AUTOSAR XML (schema 4-2-1)
standard types defined: boolean, sint16, sint8, uint16, uint8
package /ComponentTypes
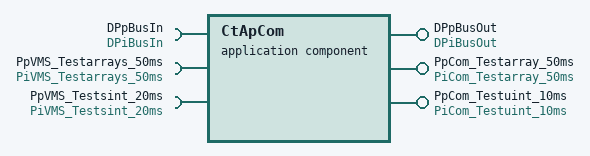
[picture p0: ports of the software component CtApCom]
  application sw component type CtApCom
    provide port DPpBusOut: provided-interface=DPiBusOut
      provided-com-specs:
        data-element=DPiBusOut/Element{0..4}, init-value=constant-reference=InitValueSpec_Reserved
        data-element=DPiBusOut/Element5, init-value=constant-reference=C_ARRAY_8_uint8
    provide port PpCom_Testarray_50ms: nonqueued-sender-com-spec{data-element=DeTestarray, init-value=constant-reference=C_RECORD_Testarray}, provided-interface=PiCom_Testarray_50ms
    provide port PpCom_Testuint_10ms: nonqueued-sender-com-spec{data-element=DeTestuint, init-value=constant-reference=C_RECORD_Testuint}, provided-interface=PiCom_Testuint_10ms
    require port DPpBusIn: required-interface=DPiBusIn
      required-com-specs:
        data-element=DPiBusIn/Element{0..4}, filter=data-filter-type=ALWAYS, init-value=constant-reference=InitValueSpec_Reserved
        data-element=DPiBusIn/Element5, filter=data-filter-type=ALWAYS, init-value=constant-reference=C_ARRAY_8_uint8
    require port PpVMS_Testarrays_50ms: nonqueued-receiver-com-spec{data-element=DeTestarrays, filter=data-filter-type=ALWAYS, init-value=constant-reference=C_RECORD_Testarrays}, required-interface=PiVMS_Testarrays_50ms
    require port PpVMS_Testsint_20ms: nonqueued-receiver-com-spec{data-element=DeTestsint, filter=data-filter-type=ALWAYS, init-value=constant-reference=C_RECORD_Testsint}, required-interface=PiVMS_Testsint_20ms
    behavior CtApCom_InternalBehavior
  composition sw component type ApplicationHost
    component CtApCom: type=CtApCom
  swc implementation CtApCom_Implementation: behavior=CtApCom_InternalBehavior
    code-descriptors:
      code Default: artifact-descriptors=autosar-engineering-object={short-label=Default, category=SWSRC}
package /Constants
  5 x constant specification:
    C_ARRAY_8_uint8: value-spec=8 x 0
    C_RECORD_Testarray: value-spec=fields=Element5:8 x 0
    C_RECORD_Testarrays: value-spec=fields=Element5:8 x 0
    C_RECORD_Testsint: value-spec=fields=[Element0:0, Element1:0, Element2:0, Element3:0, Element4:0]
    C_RECORD_Testuint: value-spec=fields=[Element0:0, Element1:0, Element2:0, Element3:0, Element4:0]
package /DataTypes
  11 x impl type, all with sw-calibration-access=READ-ONLY, type-emitter=RTE:
    Dt_Element0: category=VALUE, base-type=boolean
    Dt_Element1: category=VALUE, base-type=uint8
    Dt_Element2: category=VALUE, base-type=uint16
    Dt_Element3: category=VALUE, base-type=sint8
    Dt_Element4: category=VALUE, base-type=sint16
    Dt_Element5: category=ARRAY
      element Element: array-size=8, array-size-semantics=FIXED-SIZE, implementation-data-type=uint8
    Dt_RECORD_Testarray: category=STRUCTURE
      element Element5: implementation-data-type=Dt_Testarray
    Dt_RECORD_Testarrays: category=STRUCTURE
      element Element5: implementation-data-type=Dt_Element5
    Dt_RECORD_Testsint: category=STRUCTURE
      5 x element, all with category=TYPE_REFERENCE:
        Element0: implementation-data-type=boolean
        Element1: implementation-data-type=uint8
        Element2: implementation-data-type=uint16
        Element3: implementation-data-type=sint8
        Element4: implementation-data-type=sint16
    Dt_RECORD_Testuint: category=STRUCTURE
      5 x element, all with category=TYPE_REFERENCE:
        Element0: implementation-data-type=boolean
        Element1: implementation-data-type=uint8
        Element2: implementation-data-type=uint16
        Element3: implementation-data-type=sint8
        Element4: implementation-data-type=sint16
    Dt_Testarray: category=ARRAY
      element Element: array-size=8, array-size-semantics=FIXED-SIZE, implementation-data-type=uint8
package /DaVinci
  constant specification InitValueSpec_Reserved: value-spec=0
package /PortInterfaces
  6 x sender receiver interface:
    DPiBusIn
      6 x data:
        Element{0..5}: type=Dt_Element{0..5}
      invalidation-policys:
        data-element=DPiBusIn/Element{1..4}, handle-invalid=DONT-INVALIDATE
        data-element=DPiBusIn/Element0, handle-invalid=DONT-INVALIDATE
        data-element=DPiBusIn/Element5, handle-invalid=DONT-INVALIDATE
    DPiBusOut
      6 x data:
        Element{0..5}: type=Dt_Element{0..5}
      invalidation-policys:
        data-element=DPiBusOut/Element{1..4}, handle-invalid=DONT-INVALIDATE
        data-element=DPiBusOut/Element0, handle-invalid=DONT-INVALIDATE
        data-element=DPiBusOut/Element5, handle-invalid=DONT-INVALIDATE
    PiCom_Testarray_50ms: invalidation-policy{data-element=DeTestarray, handle-invalid=DONT-INVALIDATE}
      data DeTestarray: type=Dt_RECORD_Testarray
    PiCom_Testuint_10ms: invalidation-policy{data-element=DeTestuint, handle-invalid=DONT-INVALIDATE}
      data DeTestuint: type=Dt_RECORD_Testuint
    PiVMS_Testarrays_50ms: invalidation-policy{data-element=DeTestarrays, handle-invalid=DONT-INVALIDATE}
      data DeTestarrays: type=Dt_RECORD_Testarrays
    PiVMS_Testsint_20ms: invalidation-policy{data-element=DeTestsint, handle-invalid=DONT-INVALIDATE}
      data DeTestsint: type=Dt_RECORD_Testsint
package /System
  system System: category=SYSTEM_EXTRACT
    root-software-compositions:
      root sw composition prototype ApplicationHost: software-composition=ApplicationHost
